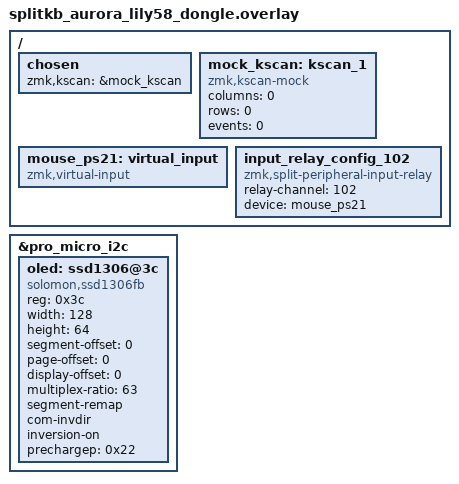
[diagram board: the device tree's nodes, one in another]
#include "splitkb_aurora_lily58.dtsi"
#include "mouse_tp.dtsi"

/ {
    chosen {
        zmk,kscan = &mock_kscan;
    };

    mock_kscan: kscan_1 {
        compatible = "zmk,kscan-mock";
        columns = <0>;
        rows = <0>;
        events = <0>;
    };
};

&pro_micro_i2c {
    status = "okay";
    
    oled: ssd1306@3c {
        compatible = "solomon,ssd1306fb";
        reg = <0x3c>;
        width = <128>;
        height = <64>;
        segment-offset = <0>;
        page-offset = <0>;
        display-offset = <0>;
        multiplex-ratio = <63>;
        segment-remap;
        com-invdir;
        inversion-on;
        prechargep = <0x22>;
    };
};

/ {
    /* define virtual input, will be resurrected for emitting input event */
	/* NOTE: set `device = <&glidepoint>` in `zmk,input-listener` */
	mouse_ps21: virtual_input {
		compatible = "zmk,virtual-input";
	};

	/* for central side, define (relay-channel)-to-(virtual-input) mapping */
	input_relay_config_102 {
		compatible = "zmk,split-peripheral-input-relay";
		
		/* channel id, used to filter incoming input event from split peripheral */
		/* NOTE: should matching relay-channel on peripheral overlay */
		relay-channel = <102>;

		/* virtual input device on central, which used to emit input event as an agent device */
		device = <&mouse_ps21>;
	};
};


&mouse_ps21 {
    status = "okay";
};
